# IMM100A register map
Vendor: Infineon; File version: 0.8.0 (Reference Manual v0.8.0)
CPU: CM0 r0p0, little endian, no MPU, no FPU, 2 interrupt priority bits
Registers are 32-bit, read-write, reset 0x0 unless marked. A register's access mark holds for its fields unless they carry their own. Offsets are from the block's base; [hi:lo] are bit positions; lines under a group give offsets from that group; {n}, {i} and the like mark numbered series; 'fields as' and 'values as' point back to an identical list.

## CAN_MO — Controller Area Networks
Base 0x50041000
{0x0+0x20*i} MO[{i}] (i=0..31) group — Message Object Registers
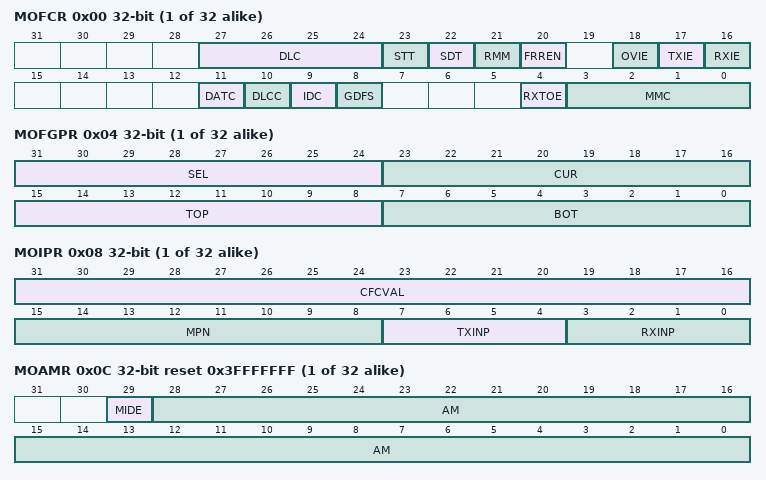
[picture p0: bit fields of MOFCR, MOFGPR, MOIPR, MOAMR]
  0x00 MOFCR — Message Object Function Control Register
    [27:24] DLC — Data Length Code
    [23] STT — Single Transmit Trial
    [22] SDT — Single Data Transfer
    [21] RMM — Transmit Object Remote Monitoring
      0=Remote monitoring is disabled: Identifier, IDE bit, and DLC of message object n remain unchanged upon the reception of a matching Remote Frame; 1=Remote monitoring is enabled: Identifier, IDE bit, and DLC of a matching Remote Frame are copied to transmit object n in order to monitor incoming Remote Frames
    [20] FRREN — Foreign Remote Request Enable
      0=TXRQ of message object n is set on reception of a matching Remote Frame; 1=TXRQ of the message object referenced by the pointer CUR is set on reception of a matching Remote Frame
    [18] OVIE — Overflow Interrupt Enable
      0=FIFO full interrupt is disabled; 1=FIFO full interrupt is enabled
    [17] TXIE — Transmit Interrupt Enable
      0=Message transmit interrupt is disabled; 1=Message transmit interrupt is enabled
    [16] RXIE — Receive Interrupt Enable
      0=Message receive interrupt is disabled; 1=Message receive interrupt is enabled
    [11] DATC — Data Copy
      0=Data fields are not copied; 1=Data fields in registers MODATALn and MODATAHn of the gateway source object (after storing the received frame in the source) are copied to the gateway destination
    [10] DLCC — Data Length Code Copy
      0=Data length code is not copied; 1=Data length code of the gateway source object (after storing the received frame in the source) is copied to the gateway destination object
    [9] IDC — Identifier Copy
      0=The identifier of the gateway source object is not copied; 1=The identifier of the gateway source object (after storing the received frame in the source) is copied to the gateway destination object
    [8] GDFS — Gateway Data Frame Send
      0=TXRQ is unchanged in the destination object; 1=TXRQ is set in the gateway destination object after the internal transfer from the gateway source to the gateway destination object
    [4] RXTOE — Receive Time-Out Enable
      0=Message does not take part in receive time-out check; 1=Message takes part in receive time-out check
    [3:0] MMC — Message Mode Control
      0=Standard Message Object; 1=Receive FIFO Base Object; 2=Transmit FIFO Base Object; 3=Transmit FIFO Slave Object; 4=Gateway Source Object
  0x04 MOFGPR — Message Object FIFO/Gateway Pointer Register
    [31:24] SEL — Object Select Pointer
    [23:16] CUR — Current Object Pointer
    [15:8] TOP — Top Pointer
    [7:0] BOT — Bottom Pointer
  0x08 MOIPR — Message Object Interrupt Pointer Register
    [31:16] CFCVAL — CAN Frame Counter Value
    [15:8] MPN — Message Pending Number
    [7:4] TXINP — Transmit Interrupt Node Pointer
      0=Interrupt output line INT_O0 is selected; 1=Interrupt output line INT_O1 is selected; 14=Interrupt output line INT_O14 is selected; 15=Interrupt output line INT_O15 is selected
    [3:0] RXINP — Receive Interrupt Node Pointer
      values as TXINP
  0x0C MOAMR reset 0x3FFFFFFF — Message Object Acceptance Mask Register
    [29] MIDE — Acceptance Mask Bit for Message IDE Bit
      0=Message object n accepts the reception of both, standard and extended frames; 1=Message object n receives frames only with matching IDE bit
    [28:0] AM — Acceptance Mask for Message Identifier
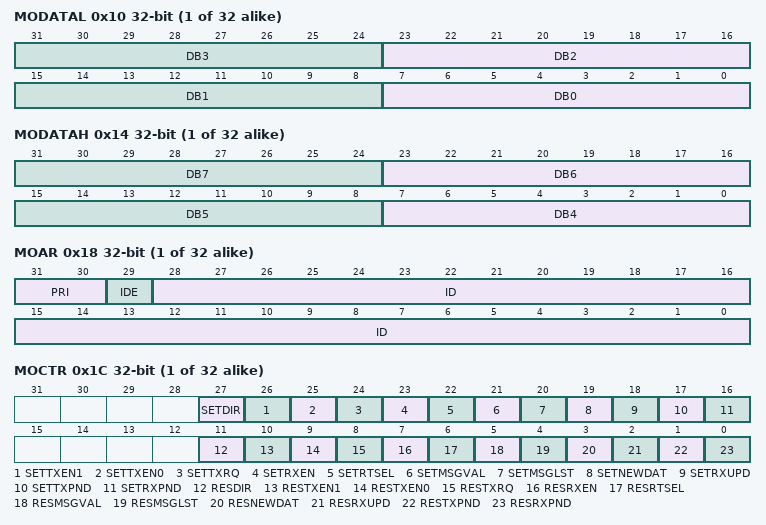
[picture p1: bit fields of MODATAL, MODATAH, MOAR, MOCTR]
  0x10 MODATAL — Message Object Data Register Low
    [8n+7:8n] DB{n} (n=0..3) — Data Byte {n} of Message Object n
  0x14 MODATAH — Message Object Data Register High
    [8n-25:8n-32] DB{n} (n=4..7) — Data Byte {n} of Message Object n
  0x18 MOAR — Message Object Arbitration Register
    [31:30] PRI — Priority Class
      1=Transmit acceptance filtering is based on the list order. This means that message object n is considered for transmission only if there is no other message object with valid transmit request (MSGVAL & TXEN0 & TXEN1 = 1) somewhere before this object in the list.; 2=Transmit acceptance filtering is based on the CAN identifier. This means, message object n is considered for transmission only if there is no other message object with higher priority identifier + IDE + DIR (with respect to CAN arbitration rules) somewhere in the list (see).; 3=Transmit acceptance filtering is based on the list order (as PRI = 01B)
    [29] IDE — Identifier Extension Bit of Message Object n
      0=Message object n handles standard frames with 11-bit identifier; 1=Message object n handles extended frames with 29-bit identifier
    [28:0] ID — CAN Identifier of Message Object n
  0x1C MOCTR wo (reset mask 0xFFFF) — Message Object Control Register
    [27] SETDIR — Reset/Set Message Direction
    [26] SETTXEN1 — Reset/Set Transmit Enable 1
    [25] SETTXEN0 — Reset/Set Transmit Enable 0
    [24] SETTXRQ — Reset/Set Transmit Request
    [23] SETRXEN — Reset/Set Receive Enable
    [22] SETRTSEL — Reset/Set Receive/Transmit Selected
    [21] SETMSGVAL — Reset/Set Message Valid
    [20] SETMSGLST — Reset/Set Message Lost
    [19] SETNEWDAT — Reset/Set New Data
    [18] SETRXUPD — Reset/Set Receive Updating
    [17] SETTXPND — Reset/Set Transmit Pending
    [16] SETRXPND — Reset/Set Receive Pending
    [11] RESDIR — Reset/Set Message Direction
    [10] RESTXEN1 — Reset/Set Transmit Enable 1
    [9] RESTXEN0 — Reset/Set Transmit Enable 0
    [8] RESTXRQ — Reset/Set Transmit Request
    [7] RESRXEN — Reset/Set Receive Enable
    [6] RESRTSEL — Reset/Set Receive/Transmit Selected
    [5] RESMSGVAL — Reset/Set Message Valid
    [4] RESMSGLST — Reset/Set Message Lost
    [3] RESNEWDAT — Reset/Set New Data
    [2] RESRXUPD — Reset/Set Receive Updating
    [1] RESTXPND — Reset/Set Transmit Pending
    [0] RESRXPND — Reset/Set Receive Pending
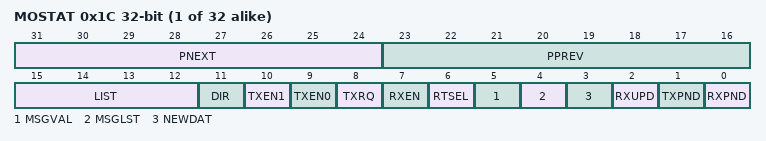
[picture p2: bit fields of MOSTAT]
  0x1C MOSTAT ro (reset mask 0xFFFF) (alternate view of MOCTR) — Message Object Status Register
    [31:24] PNEXT — Pointer to Next Message Object
    [23:16] PPREV — Pointer to Previous Message Object
    [15:12] LIST — List Allocation
    [11] DIR — Message Direction
      0=Receive Object selected: With TXRQ = 1, a Remote Frame with the identifier of message object n is scheduled for transmission. On reception of a Data Frame with matching identifier, the message is stored in message object n.; 1=Transmit Object selected: If TXRQ = 1, message object n is scheduled for transmission of a Data Frame. On reception of a Remote Frame with matching identifier, bit TXRQ is set.
    [10] TXEN1 — Transmit Enable 1
      0=Message object n is not enabled for frame transmission; 1=Message object n is enabled for frame transmission
    [9] TXEN0 — Transmit Enable 0
      values as TXEN1
    [8] TXRQ — Transmit Request
      0=No transmission of message object n is requested; 1=Transmission of message object n on the CAN bus is requested
    [7] RXEN — Receive Enable
      0=Message object n is not enabled for frame reception; 1=Message object n is enabled for frame reception
    [6] RTSEL — Receive/Transmit Selected
      0=Message object n is not selected for receive or transmit operation; 1=Message object n is selected for receive or transmit operation
    [5] MSGVAL — Message Valid
      0=Message object n is not valid; 1=Message object n is valid
    [4] MSGLST — Message Lost
      0=No CAN message is lost; 1=A CAN message is lost because NEWDAT has become set again when it has already been set
    [3] NEWDAT — New Data
      0=No update of the message object n since last flag reset; 1=Message object n has been updated
    [2] RXUPD — Receive Updating
      0=No receive update ongoing; 1=Message identifier, DLC, and data of the message object are currently updated
    [1] TXPND — Transmit Pending
      0=No CAN message has been transmitted; 1=A CAN message from message object n has been transmitted successfully over the CAN bus
    [0] RXPND — Receive Pending
      0=No CAN message has been received; 1=A CAN message has been received by the message object n, either directly or via gateway copy action
